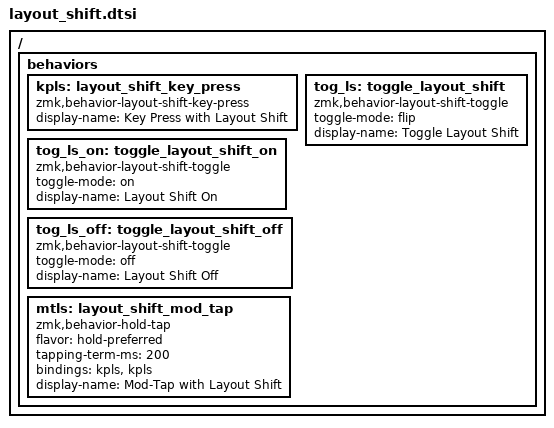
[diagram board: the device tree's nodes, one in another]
#include <dt-bindings/zmk/keys.h>
#include <layout_shift_maps.dtsi>

/ {
    behaviors {
        kpls: layout_shift_key_press {
            compatible = "zmk,behavior-layout-shift-key-press";
            #binding-cells = <1>;
            display-name = "Key Press with Layout Shift";
        };

        /omit-if-no-ref/ tog_ls: toggle_layout_shift {
            compatible = "zmk,behavior-layout-shift-toggle";
            #binding-cells = <0>;
            toggle-mode = "flip";
            display-name = "Toggle Layout Shift";
        };

        /omit-if-no-ref/ tog_ls_on: toggle_layout_shift_on {
            compatible = "zmk,behavior-layout-shift-toggle";
            #binding-cells = <0>;
            toggle-mode = "on";
            display-name = "Layout Shift On";
        };

        /omit-if-no-ref/ tog_ls_off: toggle_layout_shift_off {
            compatible = "zmk,behavior-layout-shift-toggle";
            #binding-cells = <0>;
            toggle-mode = "off";
            display-name = "Layout Shift Off";
        };

        mtls: layout_shift_mod_tap {
            compatible = "zmk,behavior-hold-tap";
            #binding-cells = <2>;
            flavor = "hold-preferred";
            tapping-term-ms = <200>;
            bindings = <&kpls>, <&kpls>;
            display-name = "Mod-Tap with Layout Shift";
        };
    };
};
